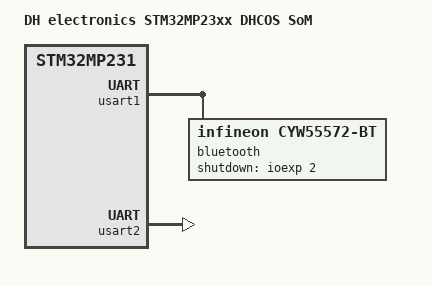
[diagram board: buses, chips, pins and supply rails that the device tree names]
// SPDX-License-Identifier: (GPL-2.0-only OR BSD-3-Clause)
/*
 * Copyright (C) 2025-2026 Marek Vasut <marex@nabladev.com>
 */

#include <dt-bindings/gpio/gpio.h>
#include <dt-bindings/input/input.h>
#include <dt-bindings/leds/common.h>
#include "stm32mp25-pinctrl.dtsi"
#include "stm32mp25xxak-pinctrl.dtsi"
#include "stm32mp2xxx-dhcos-som.dtsi"

/ {
	model = "DH electronics STM32MP23xx DHCOS SoM";
	compatible = "dh,stm32mp231a-dhcos-som", "st,stm32mp231";

	aliases {
		serial1 = &usart1;
		serial2 = &usart2;
	};
};

&rv3032 {
	interrupts-extended = <&gpiod 10 IRQ_TYPE_EDGE_FALLING>;
};

/* Bluetooth */
&usart1 {
	pinctrl-names = "default", "sleep", "idle";
	pinctrl-0 = <&usart1_pins_a>;
	pinctrl-1 = <&usart1_sleep_pins_a>;
	pinctrl-2 = <&usart1_idle_pins_a>;
	uart-has-rtscts;
	status = "okay";

	bluetooth {
		compatible = "infineon,cyw55572-bt";
		brcm,requires-autobaud-mode;
		max-speed = <3000000>;
		shutdown-gpios = <&ioexp 2 GPIO_ACTIVE_HIGH>;
	};
};

&usart2 {
	pinctrl-names = "default", "sleep", "idle";
	pinctrl-0 = <&usart2_pins_b>;
	pinctrl-1 = <&usart2_sleep_pins_b>;
	pinctrl-2 = <&usart2_idle_pins_b>;
	uart-has-rtscts;
	status = "okay";
};
